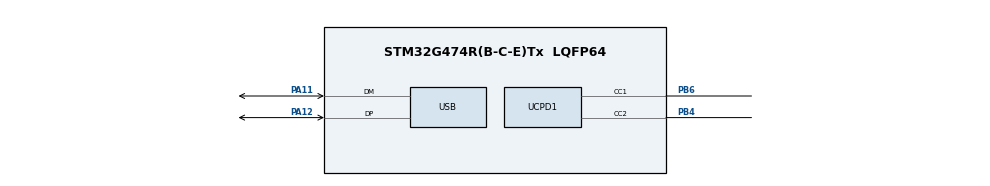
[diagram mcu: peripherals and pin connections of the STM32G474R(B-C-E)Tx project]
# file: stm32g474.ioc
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Dma.Request0=UCPD1_RX
Dma.Request1=UCPD1_TX
Dma.UCPD1_RX.0.Direction=DMA_PERIPH_TO_MEMORY
Dma.UCPD1_RX.0.EventEnable=DISABLE
Dma.UCPD1_RX.0.Instance=DMA1_Channel1
Dma.UCPD1_RX.0.MemDataAlignment=DMA_MDATAALIGN_BYTE
Dma.UCPD1_RX.0.MemInc=DMA_MINC_ENABLE
Dma.UCPD1_RX.0.Mode=DMA_NORMAL
Dma.UCPD1_RX.0.PeriphDataAlignment=DMA_PDATAALIGN_BYTE
Dma.UCPD1_RX.0.PeriphInc=DMA_PINC_DISABLE
Dma.UCPD1_RX.0.Polarity=HAL_DMAMUX_REQ_GEN_RISING
Dma.UCPD1_RX.0.Priority=DMA_PRIORITY_LOW
Dma.UCPD1_RX.0.RequestNumber=1
Dma.UCPD1_RX.0.SignalID=NONE
Dma.UCPD1_RX.0.SyncEnable=DISABLE
Dma.UCPD1_RX.0.SyncPolarity=HAL_DMAMUX_SYNC_NO_EVENT
Dma.UCPD1_RX.0.SyncRequestNumber=1
Dma.UCPD1_RX.0.SyncSignalID=NONE
Dma.UCPD1_TX.1.Direction=DMA_MEMORY_TO_PERIPH
Dma.UCPD1_TX.1.EventEnable=DISABLE
Dma.UCPD1_TX.1.Instance=DMA1_Channel2
Dma.UCPD1_TX.1.MemDataAlignment=DMA_MDATAALIGN_BYTE
Dma.UCPD1_TX.1.MemInc=DMA_MINC_ENABLE
Dma.UCPD1_TX.1.Mode=DMA_NORMAL
Dma.UCPD1_TX.1.PeriphDataAlignment=DMA_PDATAALIGN_BYTE
Dma.UCPD1_TX.1.PeriphInc=DMA_PINC_DISABLE
Dma.UCPD1_TX.1.Polarity=HAL_DMAMUX_REQ_GEN_RISING
Dma.UCPD1_TX.1.Priority=DMA_PRIORITY_LOW
Dma.UCPD1_TX.1.RequestNumber=1
Dma.UCPD1_TX.1.SignalID=NONE
Dma.UCPD1_TX.1.SyncEnable=DISABLE
Dma.UCPD1_TX.1.SyncPolarity=HAL_DMAMUX_SYNC_NO_EVENT
Dma.UCPD1_TX.1.SyncRequestNumber=1
Dma.UCPD1_TX.1.SyncSignalID=NONE
FREERTOS.Tasks01=defaultTask,24,128,StartDefaultTask,Default,NULL,Dynamic,NULL,NULL
Mcu.Family=STM32G4
Mcu.Name=STM32G474R(B-C-E)Tx
Mcu.Package=LQFP64
NVIC.DMA1_Channel1_IRQn=true\:5\:0\:false\:false\:true\:true\:false\:true
NVIC.DMA1_Channel2_IRQn=true\:5\:0\:false\:false\:true\:true\:false\:true
NVIC.PriorityGroup=NVIC_PRIORITYGROUP_4
NVIC.TIM20_UP_IRQn=true\:15\:0\:false\:false\:true\:false\:true\:true
NVIC.TimeBase=TIM20_UP_IRQn
NVIC.TimeBaseIP=TIM20
NVIC.UCPD1_IRQn=true\:5\:0\:false\:false\:true\:true\:false\:false
NVIC.USB_LP_IRQn=true\:5\:0\:false\:false\:true\:true\:false\:true
PA11.Mode=Device
PA11.Signal=USB_DM
PA12.Mode=Device
PA12.Signal=USB_DP
PA13.Mode=Serial_Wire
PA13.Signal=SYS_JTMS-SWDIO
PA14.Mode=Serial_Wire
PA14.Signal=SYS_JTCK-SWCLK
PB4.Mode=Sink_AllSignals
PB4.Signal=UCPD1_CC2
PB6.Mode=Sink_AllSignals
PB6.Signal=UCPD1_CC1
PF0-OSC_IN.Mode=HSE-External-Oscillator
PF0-OSC_IN.Signal=RCC_OSC_IN
PF1-OSC_OUT.Mode=HSE-External-Oscillator
PF1-OSC_OUT.Signal=RCC_OSC_OUT
ProjectManager.HeapSize=0x200
ProjectManager.StackSize=0x400
ProjectManager.TargetToolchain=Makefile
RCC.ADC12Freq_Value=432000000
RCC.ADC345Freq_Value=432000000
RCC.AHBFreq_Value=432000000
RCC.APB1Freq_Value=432000000
RCC.APB1TimFreq_Value=432000000
RCC.APB2Freq_Value=432000000
RCC.APB2TimFreq_Value=432000000
RCC.CortexFreq_Value=432000000
RCC.EXTERNAL_CLOCK_VALUE=12288000
RCC.HCLKFreq_Value=432000000
RCC.HSE_VALUE=24000000
RCC.HSI48_VALUE=48000000
RCC.HSI_VALUE=16000000
RCC.LSE_VALUE=32768
RCC.PLLM=RCC_PLLM_DIV3
RCC.PLLN=108
RCC.PLLQ=RCC_PLLQ_DIV6
RCC.PLLSourceVirtual=RCC_PLLSOURCE_HSE
RCC.SYSCLKFreq_VALUE=432000000
RCC.SYSCLKSource=RCC_SYSCLKSOURCE_PLLCLK
RCC.USBFreq_Value=144000000
RCC.VCOOutputFreq_Value=864000000
VP_FREERTOS_VS_CMSIS_V2.Mode=CMSIS_V2
VP_SYS_VS_DBSignals.Mode=DisableDeadBatterySignals
VP_SYS_VS_tim20.Mode=TIM20
board=custom

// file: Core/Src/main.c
/* USER CODE BEGIN Header */
/**
  ******************************************************************************
  * @file           : main.c
  * @brief          : Main program body
  ******************************************************************************
  * @attention
  *
  * Copyright (c) 2022 STMicroelectronics.
  * All rights reserved.
  *
  * This software is licensed under terms that can be found in the LICENSE file
  * in the root directory of this software component.
  * If no LICENSE file comes with this software, it is provided AS-IS.
  *
  ******************************************************************************
  */
/* USER CODE END Header */
#include "main.h"
#include "cmsis_os.h"
#include "dma.h"
#include "ucpd.h"
#include "usbpd.h"
#include "usb_device.h"
#include "gpio.h"

/* USER CODE BEGIN Includes */
#include "application.h"
//>>---------------------- Log control
#define LOG_MODULE_NAME main
#if defined(NDEBUG)
#define LOG_MODULE_LEVEL (0)
#else
#define LOG_MODULE_LEVEL (3)
#endif
#include "log_libs.h"
//<<----------------------
/* USER CODE END Includes */

void SystemClock_Config(void);
void MX_FREERTOS_Init(void);

int main(void)
{

  /* MCU Configuration--------------------------------------------------------*/

  /* Reset of all peripherals, Initializes the Flash interface and the Systick. */
  HAL_Init();

  /* Configure the system clock */
  SystemClock_Config();

  /* Initialize all configured peripherals */
  MX_GPIO_Init();
  MX_DMA_Init();
  MX_UCPD1_Init();
  MX_USB_Device_Init();

  /* Init scheduler */
  // osKernelInitialize();
  /* USBPD initialisation ---------------------------------*/
  MX_USBPD_Init();  /* Call init function for freertos objects (in freertos.c) */
  // MX_FREERTOS_Init();

  /* Start scheduler */
  // osKernelStart();
  /* We should never get here as control is now taken by the scheduler */
  /* Infinite loop */
  /* USER CODE BEGIN WHILE */
  while (1)
  {
    application();
    /* USER CODE END WHILE */

  }
}

void SystemClock_Config(void)
{
  LL_FLASH_SetLatency(LL_FLASH_LATENCY_4);
  while(LL_FLASH_GetLatency() != LL_FLASH_LATENCY_4)
  {
  }
  LL_PWR_SetRegulVoltageScaling(LL_PWR_REGU_VOLTAGE_SCALE1);
  LL_RCC_HSI_Enable();
   /* Wait till HSI is ready */
  while(LL_RCC_HSI_IsReady() != 1)
  {
  }

  LL_RCC_HSI_SetCalibTrimming(64);
  LL_RCC_PLL_ConfigDomain_SYS(LL_RCC_PLLSOURCE_HSI, LL_RCC_PLLM_DIV_6, 108, LL_RCC_PLLR_DIV_2);
  LL_RCC_PLL_ConfigDomain_48M(LL_RCC_PLLSOURCE_HSI, LL_RCC_PLLM_DIV_6, 108, LL_RCC_PLLQ_DIV_6);
  LL_RCC_PLL_EnableDomain_SYS();
  LL_RCC_PLL_EnableDomain_48M();
  LL_RCC_PLL_Enable();
   /* Wait till PLL is ready */
  while(LL_RCC_PLL_IsReady() != 1)
  {
  }

  LL_RCC_SetSysClkSource(LL_RCC_SYS_CLKSOURCE_PLL);
  LL_RCC_SetAHBPrescaler(LL_RCC_SYSCLK_DIV_2);
   /* Wait till System clock is ready */
  while(LL_RCC_GetSysClkSource() != LL_RCC_SYS_CLKSOURCE_STATUS_PLL)
  {
  }

  /* Insure 1us transition state at intermediate medium speed clock*/
  for (__IO uint32_t i = (170 >> 1); i !=0; i--);

  /* Set AHB prescaler*/
  LL_RCC_SetAHBPrescaler(LL_RCC_SYSCLK_DIV_1);
  LL_RCC_SetAPB1Prescaler(LL_RCC_APB1_DIV_1);
  LL_RCC_SetAPB2Prescaler(LL_RCC_APB2_DIV_1);
  LL_SetSystemCoreClock(144000000);

   /* Update the time base */
  if (HAL_InitTick (TICK_INT_PRIORITY) != HAL_OK)
  {
    Error_Handler();
  }
}

void HAL_TIM_PeriodElapsedCallback(TIM_HandleTypeDef *htim)
{
  if (htim->Instance == TIM8) {
    HAL_IncTick();
  }
}

void Error_Handler(void)
{
  __disable_irq();
  while (1)
  {
  }
}
